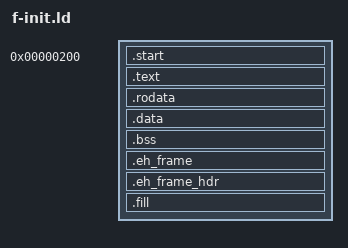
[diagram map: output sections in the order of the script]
ENTRY(_start)

SECTIONS {

    . = 0x200;

    .start : {
        *(.start)
    }

    .text : {
        *(.text .text.*)
    }

    .rodata : {
        *(.rodata .rodata.*)
    }

    .data : {
        *(.data .data.*)
    }

    .bss : {
        _bss_start = .;
        *(.bss .bss.*)
        _bss_end = .;
    }

    .eh_frame : {
        *(.eh_frame .eh_frame.*)
    }

    .eh_frame_hdr : {
        *(.eh_frame_hdr .eh_frame_hdr.*)
    }

    .fill : {
        FILL(0x00);
        . = 0x5f00;
    }


}
